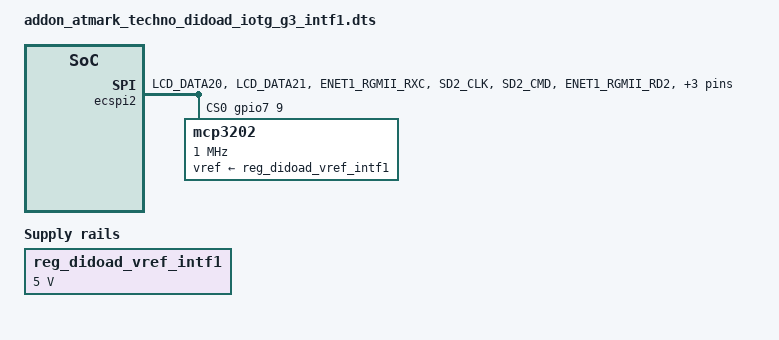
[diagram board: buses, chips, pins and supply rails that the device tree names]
/*
 * Copyright (C) 2017 Atmark Techno, Inc. All Rights Reserved.
 * Author: Daisuke Mizobuchi <mizo@atmark-techno.com>
 *
 * This program is free software; you can redistribute it and/or
 * modify it under the terms of the GNU General Public License
 * version 2 as published by the Free Software Foundation.
 */

#include "../../../../arch/arm/boot/dts/imx7d-pinfunc.h"

/dts-v1/;
/plugin/;
/ {
	fragment@0 {
		target = <&iomuxc>;
		__overlay__ {
			addon-intf1 {
				pinctrl_ecspi2: ecspi2grp {
					fsl,pins = <
						MX7D_PAD_LCD_DATA20__GPIO3_IO25		0x40000000	/* INTF1_24 */
						MX7D_PAD_LCD_DATA21__GPIO3_IO26		0x40000000	/* INTF1_25 */
						MX7D_PAD_ENET1_RGMII_RXC__GPIO7_IO5	0x00	/* INTF1_43 */
						MX7D_PAD_SD2_CLK__GPIO5_IO12		0x70	/* INTF1_47 */
						MX7D_PAD_SD2_CMD__GPIO5_IO13		0x70	/* INTF1_48 */

						MX7D_PAD_ENET1_RGMII_RD2__ECSPI2_SCLK	0x70	/* INTF1_35 */
						MX7D_PAD_ENET1_RGMII_TD2__ECSPI2_MISO	0x70	/* INTF1_36 */
						MX7D_PAD_ENET1_RGMII_RD3__ECSPI2_MOSI	0x70	/* INTF1_37 */
						MX7D_PAD_ENET1_RGMII_TD3__GPIO7_IO9	0x70	/* INTF1_50 */
					>;
				};
			};
		};
	};

	fragment@1 {
		target = <&ecspi2>;
		__overlay__ {
			pinctrl-names = "default";
			pinctrl-0 = <&pinctrl_ecspi2>;
			fsl,spi-num-chipselects = <1>;
			cs-gpios = <&gpio7 9 0>;
			status = "okay";

			#address-cells = <1>;
			#size-cells = <0>;
			mcp3202@0 {
				compatible = "mcp3202";
				spi-max-frequency = <1000000>;
				reg = <0>;
				vref-supply = <&reg_didoad_vref_intf1>;
			};
		};
	};

	fragment@2 {
		target = <&regulators>;
		__overlay__ {
			reg_didoad_vref_intf1: reg_didoad_vref_con1 {
				compatible = "regulator-fixed";
				regulator-name = "DIDOAD_VREF";
				regulator-min-microvolt = <5000000>;
				regulator-max-microvolt = <5000000>;
				regulator-always-on;
			};
		};
	};

};
